# ATSAMD21GxAU register map
Vendor: Microchip Technology Inc.; Series: SAMD21; File version: D
CPU: CM0+ r0p1, little endian, no MPU, no FPU, VTOR, 2 interrupt priority bits, 28 interrupts
Registers are 8-bit, read-write, reset 0x0 unless marked. A register's access mark holds for its fields unless they carry their own. Offsets are from the block's base; [hi:lo] are bit positions; {n}, {i} and the like mark numbered series; 'fields as' and 'values as' point back to an identical list.

## DMAC — Direct Memory Access Controller
Base 0x41004800; register names take the prefix DMAC_
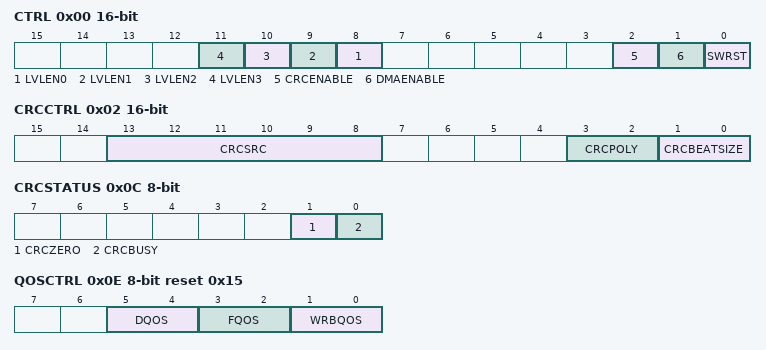
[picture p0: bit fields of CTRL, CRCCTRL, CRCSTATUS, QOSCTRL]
0x00 CTRL 16-bit — Control
  [n+8] LVLEN{n} (n=0..3) — Priority Level {n} Enable
  [2] CRCENABLE
  [1] DMAENABLE
  [0] SWRST — Software Reset
0x02 CRCCTRL 16-bit — CRC Control
  [13:8] CRCSRC — CRC Input Source
    0=NOACT (No action); 1=IO (I/O interface)
  [3:2] CRCPOLY — CRC Polynomial Type
    0=CRC16 (CRC-16 (CRC-CCITT)); 1=CRC32 (CRC32 (IEEE 802.3))
  [1:0] CRCBEATSIZE
    0=BYTE (8-bit bus transfer); 1=HWORD (16-bit bus transfer); 2=WORD (32-bit bus transfer)
0x04 CRCDATAIN 32-bit — CRC Data Input
0x08 CRCCHKSUM 32-bit — CRC Checksum
0x0C CRCSTATUS
  [1] CRCZERO ro
  [0] CRCBUSY — CRC Module Busy
0x0D DBGCTRL — Debug Control
  [0] DBGRUN — Debug Run
0x0E QOSCTRL reset 0x15 — QOS Control
  [all] fields
    0=DISABLE (Background (no sensitive operation)); 1=LOW (Sensitive Bandwidth); 2=MEDIUM (Sensitive Latency); 3=HIGH (Critical Latency)
  [5:4] DQOS — Data Transfer Quality of Service
  [3:2] FQOS — Fetch Quality of Service
  [1:0] WRBQOS — Write-Back Quality of Service
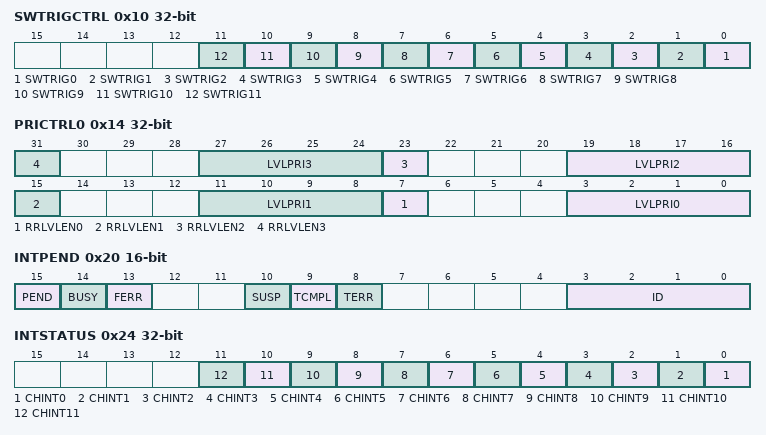
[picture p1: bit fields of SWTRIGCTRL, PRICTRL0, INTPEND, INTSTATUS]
0x10 SWTRIGCTRL 32-bit — Software Trigger Control
  [n] SWTRIG{n} (n=0..11) — Channel {n} Software Trigger
0x14 PRICTRL0 32-bit — Priority Control 0
  [8n+7] RRLVLEN{n} (n=0..3) — Level {n} Round-Robin Scheduling Enable
  [8n+3:8n] LVLPRI{n} (n=0..3) — Level {n} Channel Priority Number
0x20 INTPEND 16-bit — Interrupt Pending
  [15] PEND ro — Pending
  [14] BUSY ro
  [13] FERR ro — Fetch Error
  [10] SUSP — Channel Suspend
  [9] TCMPL — Transfer Complete
  [8] TERR — Transfer Error
  [3:0] ID — Channel ID
0x24 INTSTATUS 32-bit ro — Interrupt Status
  [n] CHINT{n} (n=0..11) — Channel {n} Pending Interrupt
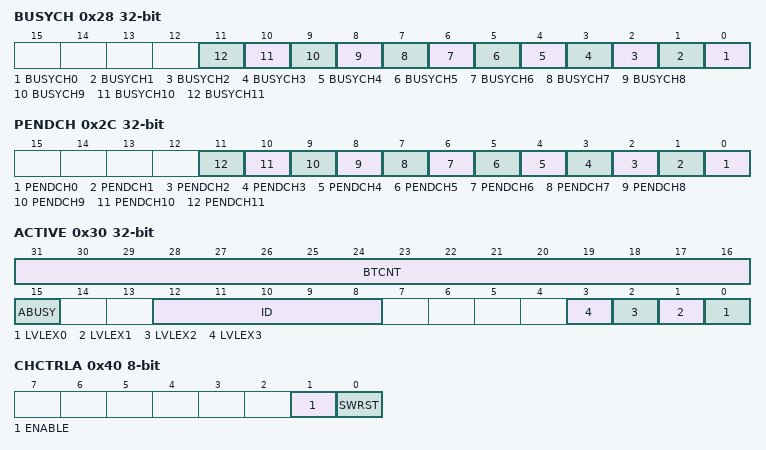
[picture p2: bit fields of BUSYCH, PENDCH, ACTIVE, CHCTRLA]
0x28 BUSYCH 32-bit ro — Busy Channels
  [n] BUSYCH{n} (n=0..11) — Busy Channel {n}
0x2C PENDCH 32-bit ro — Pending Channels
  [n] PENDCH{n} (n=0..11) — Pending Channel {n}
0x30 ACTIVE 32-bit ro — Active Channel and Levels
  [31:16] BTCNT — Active Channel Block Transfer Count
  [15] ABUSY — Active Channel Busy
  [12:8] ID — Active Channel ID
  [n] LVLEX{n} (n=0..3) — Level {n} Channel Trigger Request Executing
0x34 BASEADDR 32-bit — Descriptor Memory Section Base Address
  [31:0] BASEADDR — Descriptor Memory Base Address
0x38 WRBADDR 32-bit — Write-Back Memory Section Base Address
  [31:0] WRBADDR — Write-Back Memory Base Address
0x3F CHID — Channel ID
  [3:0] ID
0x40 CHCTRLA — Channel Control A
  [1] ENABLE — Channel Enable
  [0] SWRST — Channel Software Reset
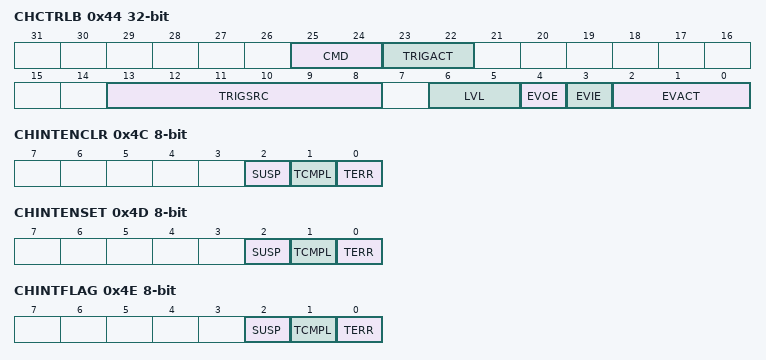
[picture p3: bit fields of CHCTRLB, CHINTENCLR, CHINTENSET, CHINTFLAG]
0x44 CHCTRLB 32-bit — Channel Control B
  [25:24] CMD — Software Command
    0=NOACT (No action); 1=SUSPEND (Channel suspend operation); 2=RESUME (Channel resume operation)
  [23:22] TRIGACT — Trigger Action
    0=BLOCK (One trigger required for each block transfer); 2=BEAT (One trigger required for each beat transfer); 3=TRANSACTION (One trigger required for each transaction)
  [13:8] TRIGSRC — Trigger Source
    0=DISABLE (Only software/event triggers)
  [6:5] LVL — Channel Arbitration Level
    {v}=Channel Priority Level {v} (v=0..3)
  [4] EVOE — Channel Event Output Enable
  [3] EVIE — Channel Event Input Enable
  [2:0] EVACT — Event Input Action
    0=NOACT (No action); 1=TRIG (Transfer and periodic transfer trigger); 2=CTRIG (Conditional transfer trigger); 3=CBLOCK (Conditional block transfer); 4=SUSPEND (Channel suspend operation); 5=RESUME (Channel resume operation); 6=SSKIP (Skip next block suspend action)
0x4C CHINTENCLR — Channel Interrupt Enable Clear
  [2] SUSP — Channel Suspend Interrupt Enable
  [1] TCMPL — Channel Transfer Complete Interrupt Enable
  [0] TERR — Channel Transfer Error Interrupt Enable
0x4D CHINTENSET — Channel Interrupt Enable Set
  fields as CHINTENCLR
0x4E CHINTFLAG — Channel Interrupt Flag Status and Clear
  [2] SUSP — Channel Suspend
  [1] TCMPL — Channel Transfer Complete
  [0] TERR — Channel Transfer Error
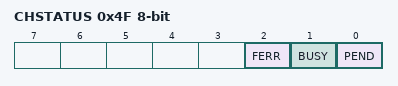
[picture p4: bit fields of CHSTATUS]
0x4F CHSTATUS ro — Channel Status
  [2] FERR — Channel Fetch Error
  [1] BUSY — Channel Busy
  [0] PEND — Channel Pending

## Notices in the file
Copyright (c) 2018 Microchip Technology Inc.
SPDX-License-Identifier: Apache-2.0
Licensed under the Apache License, Version 2.0 (the "License");
you may not use this file except in compliance with the License.
You may obtain a copy of the License at
http://www.apache.org/licenses/LICENSE-2.0
Unless required by applicable law or agreed to in writing, software
distributed under the License is distributed on an "AS IS" BASIS,
WITHOUT WARRANTIES OR CONDITIONS OF ANY KIND, either express or implied.
See the License for the specific language governing permissions and
limitations under the License.
